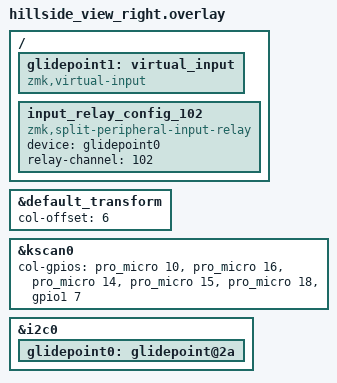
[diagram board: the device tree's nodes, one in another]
/*
 * Copyright (c) 2022 The ZMK Contributors
 *
 * SPDX-License-Identifier: MIT
 */

#include "hillside_view.dtsi"

&default_transform {
  col-offset = <6>;
};

&kscan0 {
  col-gpios
    = <&pro_micro 10 GPIO_ACTIVE_HIGH>
    , <&pro_micro 16 GPIO_ACTIVE_HIGH>
    , <&pro_micro 14 GPIO_ACTIVE_HIGH>
    , <&pro_micro 15 GPIO_ACTIVE_HIGH>
    , <&pro_micro 18 GPIO_ACTIVE_HIGH>
    , <&gpio1 7 GPIO_ACTIVE_HIGH>
    ;
};

// &right_encoder {
//   status = "okay";
// };

// trackball bus
/* &spi0 { */
/*   status = "okay"; */
/*   sck-pin = <20>; */
/*   mosi-pin = <17>; */
/*   miso-pin = <17>; // same as mosi (3-wire spi) */
/*   cs-gpios = <&gpio0 22 GPIO_ACTIVE_LOW>; */
/* }; */

/* &trackball { */
/*   status = "okay"; */
/*   irq-gpios = <&gpio0 24 (GPIO_ACTIVE_LOW | GPIO_PULL_UP)>; */
/* }; */


// &chosen {
//   zephyr,display = &nice_view;
// };

// &nice_view_spi {
//   status = "okay";
// };

// &nice_view {
//   status = "okay";
// };

&i2c0 {
  status = "okay";
  glidepoint0: glidepoint@2a {
      status = "okay";
  };
};

/ {
    /* THIS only makes keymap binding happy, nothing happens on peripheral side */
  glidepoint1: virtual_input {
		compatible = "zmk,virtual-input";
	};

  input_relay_config_102 {
    compatible = "zmk,split-peripheral-input-relay";

    /* peripheral side input device, used to... */
    /*  - be intecepted on peripheral; */
    /*  - and then, be resurrected as `zmk,virtual-device` on central; */
    device = <&glidepoint0>;

    /* channel id, used to be be transfered along with all input events. */
    /* NOTE 1: pick any 8bit integer. (1 - 255) */
    /* TE 2: should matching relay-channel on central overlay */
    relay-channel = <102>;
  };
};
